# output_remap: IP-XACT component
VLNV tenstorrent.com:ocah:output_remap:1.0

## Address spaces and blocks
output_remap_mmap.output_remap: base 'h0, range 'h8, width 64

## Registers
Registers are 64-bit, read-write, reset 0x0 unless marked. A register's access mark holds for its fields unless they carry their own. Offsets are from the block's base; lines under a group give offsets from that group; [hi:lo] are bit positions; {n}, {i} and the like mark numbered series; 'fields as' and 'values as' point back to an identical list; <NAME> marks a mode.

## output_remap_mmap.output_remap — Address-translation registers that remap outbound transactions and tag their attributes.
Base 0x00000000
0x00 REGION group
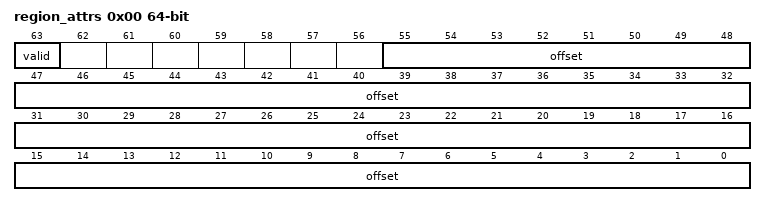
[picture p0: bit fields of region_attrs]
  0x00 region_attrs
    [63] valid — If set, accesses to this region are remapped by offset; if clear, they pass through with their address unchanged
    [55:0] offset — Address translation for remap region. RTL will use the number of bits appropriate for region granulaity. e.g. SMC: 8 * 1MB regions --> 20 bits of address space per region, 36 MSBs from this register used SEP: 16 * 512KB regions --> 19 bits of address space per region, 37 MSBs from this register used

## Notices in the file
SPDX-License-Identifier: Apache-2.0
SPDX-FileCopyrightText: 2026 Tenstorrent USA, Inc.
